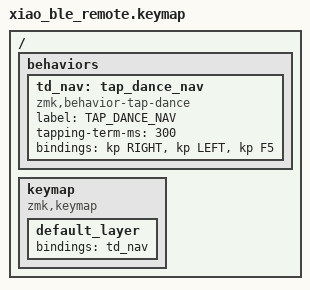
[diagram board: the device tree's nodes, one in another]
#include <behaviors.dtsi>
#include <dt-bindings/zmk/keys.h>
#include <dt-bindings/zmk/bt.h>

/ {
    behaviors {
        // Tap Dance: 1=Next, 2=Prev, 3=F5
        td_nav: tap_dance_nav {
            compatible = "zmk,behavior-tap-dance";
            label = "TAP_DANCE_NAV";
            #binding-cells = <0>;
            tapping-term-ms = <300>; // ダブルクリックの受付時間（調整可能）
            bindings = <&kp RIGHT>, <&kp LEFT>, <&kp F5>;
        };
    };

    keymap {
        compatible = "zmk,keymap";

        default_layer {
            bindings = <&td_nav>;
        };
    };
};
